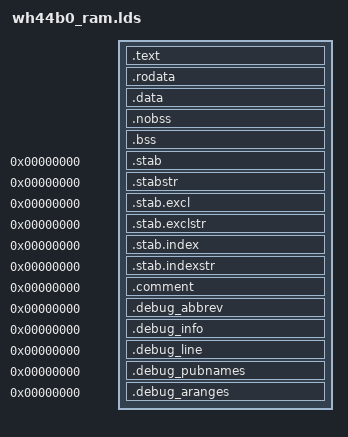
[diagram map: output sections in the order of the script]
OUTPUT_FORMAT("elf32-littlearm", "elf32-littlearm", "elf32-littlearm")
OUTPUT_ARCH(arm)
ENTRY(_start)
SECTIONS
{
    . = 0x0c000000;

    . = ALIGN(4);
    .text : {
        *(.init)
        *(.text)
    }

    . = ALIGN(4);
    .rodata : { *(.rodata) }

    . = ALIGN(4);
    .data : { *(.data) }

    . = ALIGN(4);
    .nobss : { *(.nobss) }

    . = ALIGN(4);
    __bss_start = .;
    .bss : { *(.bss) }
    __bss_end = .;

    /* stabs debugging sections. */
    .stab 0 : { *(.stab) }
    .stabstr 0 : { *(.stabstr) }
    .stab.excl 0 : { *(.stab.excl) }
    .stab.exclstr 0 : { *(.stab.exclstr) }
    .stab.index 0 : { *(.stab.index) }
    .stab.indexstr 0 : { *(.stab.indexstr) }
    .comment 0 : { *(.comment) }
    .debug_abbrev 0 : { *(.debug_abbrev) }
    .debug_info 0 : { *(.debug_info) }
    .debug_line 0 : { *(.debug_line) }
    .debug_pubnames 0 : { *(.debug_pubnames) }
    .debug_aranges 0 : { *(.debug_aranges) }

    _end = .;
}
